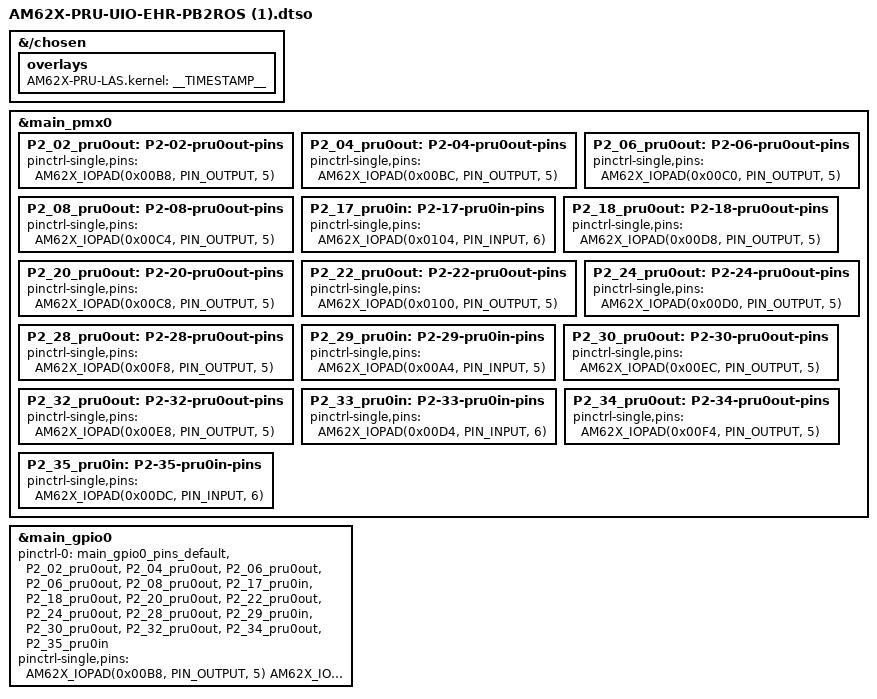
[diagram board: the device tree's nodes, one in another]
/dts-v1/;
/plugin/;

#include <dt-bindings/gpio/gpio.h>
#include "ti/k3-pinctrl.h"

/*
 * Helper to show loaded overlays under: /proc/device-tree/chosen/overlays/
 */
&{/chosen} {
        overlays {
                AM62X-PRU-LAS.kernel = __TIMESTAMP__;
        };
};

&main_pmx0 {
	P2_02_pru0out: P2-02-pru0out-pins {
		pinctrl-single,pins = <
			AM62X_IOPAD(0x00B8, PIN_OUTPUT, 5) /* (U22) VOUT0_DATA0.PR0_PRU0_GPO8 */
		>;
	};

	P2_04_pru0out: P2-04-pru0out-pins {
		pinctrl-single,pins = <
			AM62X_IOPAD(0x00BC, PIN_OUTPUT, 5) /* (V24) VOUT0_DATA1.PR0_PRU0_GPO9 */
		>;
	};

	P2_06_pru0out: P2-06-pru0out-pins {
		pinctrl-single,pins = <
			AM62X_IOPAD(0x00C0, PIN_OUTPUT, 5) /* (W25) VOUT0_DATA2.PR0_PRU0_GPO10 */
		>;
	};

	P2_08_pru0out: P2-08-pru0out-pins {
		pinctrl-single,pins = <
			AM62X_IOPAD(0x00C4, PIN_OUTPUT, 5) /* (W24) VOUT0_DATA3.PR0_PRU0_GPO11 */
		>;
	};

	P2_17_pru0in: P2-17-pru0in-pins {
		pinctrl-single,pins = <
			AM62X_IOPAD(0x0104, PIN_INPUT, 6) /* (AC24) VOUT0_PCLK.PR0_PRU0_GPI19 */
		>;
	};

	P2_18_pru0out: P2-18-pru0out-pins {
		pinctrl-single,pins = <
			AM62X_IOPAD(0x00D8, PIN_OUTPUT, 5) /* (V21) VOUT0_DATA8.PR0_PRU0_GPO17 */
		>;
	};

	P2_20_pru0out: P2-20-pru0out-pins {
		pinctrl-single,pins = <
			AM62X_IOPAD(0x00C8, PIN_OUTPUT, 5) /* (Y25) VOUT0_DATA4.PR0_PRU0_GPO12 */
		>;
	};

	P2_22_pru0out: P2-22-pru0out-pins {
		pinctrl-single,pins = <
			AM62X_IOPAD(0x0100, PIN_OUTPUT, 5) /* (AC25) VOUT0_VSYNC.PR0_PRU0_GPO18 */
		>;
	};

	P2_24_pru0out: P2-24-pru0out-pins {
		pinctrl-single,pins = <
			AM62X_IOPAD(0x00D0, PIN_OUTPUT, 5) /* (Y23) VOUT0_DATA6.PR0_PRU0_GPO14 */
		>;
	};

	P2_28_pru0out: P2-28-pru0out-pins {
		pinctrl-single,pins = <
			AM62X_IOPAD(0x00F8, PIN_OUTPUT, 5) /* (AB24) VOUT0_HSYNC.PR0_PRU0_GPO6 */
		>;
	};

	P2_29_pru0in: P2-29-pru0in-pins {
		pinctrl-single,pins = <
			AM62X_IOPAD(0x00A4, PIN_INPUT, 5) /* (M22) GPMC0_DIR.PR0_PRU0_GPI16 */
		>;
	};

	P2_30_pru0out: P2-30-pru0out-pins {
		pinctrl-single,pins = <
			AM62X_IOPAD(0x00EC, PIN_OUTPUT, 5) /* (AA24) VOUT0_DATA13.PR0_PRU0_GPO3 */
		>;
	};

	P2_32_pru0out: P2-32-pru0out-pins {
		pinctrl-single,pins = <
			AM62X_IOPAD(0x00E8, PIN_OUTPUT, 5) /* (AB25) VOUT0_DATA12.PR0_PRU0_GPO2 */
		>;
	};

	P2_33_pru0in: P2-33-pru0in-pins {
		pinctrl-single,pins = <
			AM62X_IOPAD(0x00D4, PIN_INPUT, 6) /* (AA25) VOUT0_DATA7.PR0_PRU0_GPI15 */
		>;
	};

	P2_34_pru0out: P2-34-pru0out-pins {
		pinctrl-single,pins = <
			AM62X_IOPAD(0x00F4, PIN_OUTPUT, 5) /* (AA21) VOUT0_DATA15.PR0_PRU0_GPO5 */
		>;
	};

	P2_35_pru0in: P2-35-pru0in-pins {
		pinctrl-single,pins = <
			AM62X_IOPAD(0x00DC, PIN_INPUT, 6) /* (W21) VOUT0_DATA9.PR0_PRU0_GPI16 */
		>;
	};
};

&main_gpio0 {
        pinctrl-0 = <&main_gpio0_pins_default &P2_02_pru0out &P2_04_pru0out &P2_06_pru0out &P2_06_pru0out &P2_08_pru0out &P2_17_pru0in &P2_18_pru0out &P2_20_pru0out &P2_22_pru0out &P2_24_pru0out &P2_28_pru0out &P2_29_pru0in &P2_30_pru0out &P2_32_pru0out &P2_34_pru0out &P2_35_pru0in>;
		pinctrl-single,pins = <
                AM62X_IOPAD(0x00B8, PIN_OUTPUT, 5) /* (U22) VOUT0_DATA0.PR0_PRU0_GPO8 */
				AM62X_IOPAD(0x00BC, PIN_OUTPUT, 5) /* (V24) VOUT0_DATA1.PR0_PRU0_GPO9 */
				AM62X_IOPAD(0x00C0, PIN_OUTPUT, 5) /* (W25) VOUT0_DATA2.PR0_PRU0_GPO10 */
				AM62X_IOPAD(0x00C4, PIN_OUTPUT, 5) /* (W24) VOUT0_DATA3.PR0_PRU0_GPO11 */
				AM62X_IOPAD(0x0104, PIN_INPUT, 6) /* (AC24) VOUT0_PCLK.PR0_PRU0_GPI19 */
				AM62X_IOPAD(0x00D8, PIN_OUTPUT, 5) /* (V21) VOUT0_DATA8.PR0_PRU0_GPO17 */
				AM62X_IOPAD(0x00C8, PIN_OUTPUT, 5) /* (Y25) VOUT0_DATA4.PR0_PRU0_GPO12 */
				AM62X_IOPAD(0x0100, PIN_OUTPUT, 5) /* (AC25) VOUT0_VSYNC.PR0_PRU0_GPO18 */
				AM62X_IOPAD(0x00D0, PIN_OUTPUT, 5) /* (Y23) VOUT0_DATA6.PR0_PRU0_GPO14 */
				AM62X_IOPAD(0x00F8, PIN_OUTPUT, 5) /* (AB24) VOUT0_HSYNC.PR0_PRU0_GPO6 */
				AM62X_IOPAD(0x00A4, PIN_INPUT, 5) /* (M22) GPMC0_DIR.PR0_PRU0_GPI16 */
				AM62X_IOPAD(0x00EC, PIN_OUTPUT, 5) /* (AA24) VOUT0_DATA13.PR0_PRU0_GPO3 */
				AM62X_IOPAD(0x00E8, PIN_OUTPUT, 5) /* (AB25) VOUT0_DATA12.PR0_PRU0_GPO2 */
				AM62X_IOPAD(0x00D4, PIN_INPUT, 6) /* (AA25) VOUT0_DATA7.PR0_PRU0_GPI15 */
				AM62X_IOPAD(0x00F4, PIN_OUTPUT, 5) /* (AA21) VOUT0_DATA15.PR0_PRU0_GPO5 */
				AM62X_IOPAD(0x00DC, PIN_INPUT, 6) /* (W21) VOUT0_DATA9.PR0_PRU0_GPI16 */
        >;

};
